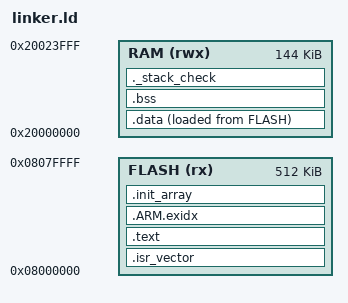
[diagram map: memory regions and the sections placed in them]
/* STM32G0B1RET6: 512 KiB flash, 144 KiB SRAM */

ENTRY(Reset_Handler)

MEMORY
{
  FLASH (rx)  : ORIGIN = 0x08000000, LENGTH = 512K
  RAM   (rwx) : ORIGIN = 0x20000000, LENGTH = 144K
}

_estack = ORIGIN(RAM) + LENGTH(RAM);
_min_stack_size = 0x1000;

SECTIONS
{
  .isr_vector :
  {
    . = ALIGN(4);
    KEEP(*(.isr_vector))
    . = ALIGN(4);
  } > FLASH

  .text :
  {
    . = ALIGN(4);
    *(.text*)
    *(.rodata*)
    KEEP(*(.init))
    KEEP(*(.fini))
    . = ALIGN(4);
  } > FLASH

  .ARM.exidx :
  {
    *(.ARM.exidx*)
  } > FLASH

  .init_array :
  {
    PROVIDE_HIDDEN(__init_array_start = .);
    KEEP(*(.init_array*))
    PROVIDE_HIDDEN(__init_array_end = .);
  } > FLASH

  _sidata = LOADADDR(.data);

  .data :
  {
    . = ALIGN(4);
    _sdata = .;
    *(.data*)
    . = ALIGN(4);
    _edata = .;
  } > RAM AT > FLASH

  .bss (NOLOAD) :
  {
    . = ALIGN(4);
    _sbss = .;
    *(.bss*)
    *(COMMON)
    . = ALIGN(4);
    _ebss = .;
  } > RAM

  /* Heap (unused) starts here; fail the link if the stack would not fit. */
  ._stack_check (NOLOAD) :
  {
    . = ALIGN(8);
    PROVIDE(end = .);
    PROVIDE(_end = .);
    . = . + _min_stack_size;
  } > RAM

  /DISCARD/ :
  {
    *(.ARM.attributes)
  }
}
